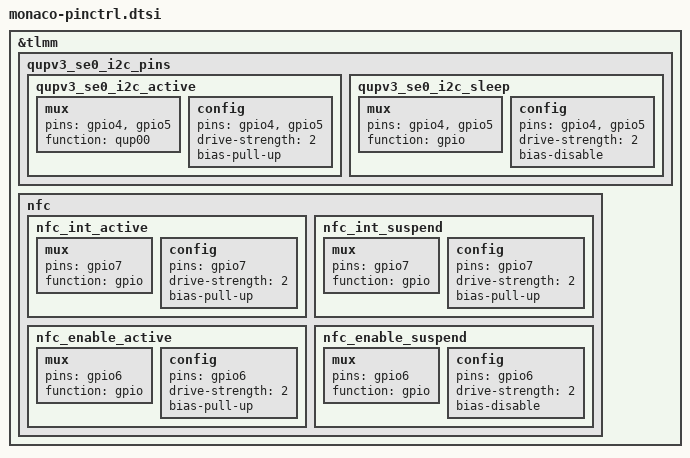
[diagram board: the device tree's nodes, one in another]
&tlmm {

	qupv3_se0_i2c_pins: qupv3_se0_i2c_pins {
				qupv3_se0_i2c_active: qupv3_se0_i2c_active {
					mux {
						pins = "gpio4", "gpio5";
						function = "qup00";
					};
	 
					config {
						pins = "gpio4", "gpio5";
						drive-strength = <2>;
						bias-pull-up;
					};
				};
	 
				qupv3_se0_i2c_sleep: qupv3_se0_i2c_sleep {
					mux {
						pins = "gpio4", "gpio5";
						function = "gpio";
					};
	 
					config {
						pins = "gpio4", "gpio5";
						drive-strength = <2>;
						bias-disable;
					};
				};
	};

	nfc {
			nfc_int_active: nfc_int_active {
				/* active state */
				mux {
					/* NFC Read Interrupt */
					pins = "gpio7";
					function = "gpio";
				};

				config {
					pins = "gpio7";
					drive-strength = <2>; /* 2 MA */
					bias-pull-up;
				};
			};

			nfc_int_suspend: nfc_int_suspend {
				/* sleep state */
				mux {
					/* NFC Read Interrupt */
					pins = "gpio7";
					function = "gpio";
				};

				config {
					pins = "gpio7";
					drive-strength = <2>; /* 2 MA */
					bias-pull-up;
				};
			};

			nfc_enable_active: nfc_enable_active {
				/* active state */
				mux {
					/* Enable */
					pins = "gpio6";
					function = "gpio";
				};

				config {
					pins = "gpio6";
					drive-strength = <2>; /* 2 MA */
					bias-pull-up;
				};
			};

			nfc_enable_suspend: nfc_enable_suspend {
				/* sleep state */
				mux {
					/* Enable */
					pins = "gpio6";
					function = "gpio";
				};

				config {
					pins = "gpio6";
					drive-strength = <2>; /* 2 MA */
					bias-disable;
				};
			};
	}; //nfc
}; //tlmm
